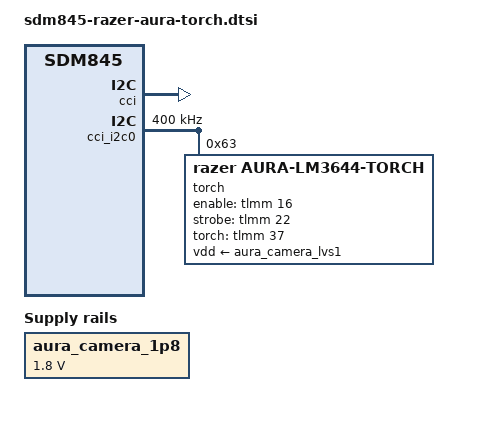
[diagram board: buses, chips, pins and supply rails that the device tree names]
// SPDX-License-Identifier: GPL-2.0-only
/* Stock RC2 camera CCI0, 0x63, HWEN16 / STROBE22 / TORCH37, LVS1 1.8 V. */
/ {
	aura_camera_1p8: regulator-camera-1p8 {
		compatible = "regulator-fixed";
		regulator-name = "aura-camera-1p8";
		regulator-min-microvolt = <1800000>;
		regulator-max-microvolt = <1800000>;
	};
};
&apps_rsc {
	regulators-0 {
		vin-lvs-1-2-supply = <&aura_camera_1p8>;
		aura_camera_lvs1: lvs1 {
			regulator-min-microvolt = <1800000>;
			regulator-max-microvolt = <1800000>;
		};
	};
};
&tlmm {
	aura_torch_pins: torch-pins-state {
		pins = "gpio16", "gpio22", "gpio37";
		function = "gpio";
		drive-strength = <2>;
		bias-pull-down;
	};
};
&cci {
	status = "okay";
	/* Only the first camera control bus is needed for torch bring-up. */
	pinctrl-0 = <&cci0_default>;
	pinctrl-1 = <&cci0_sleep>;
};
&cci_i2c0 {
	clock-frequency = <400000>;
	torch@63 {
		compatible = "razer,aura-lm3644-torch";
		reg = <0x63>;
		vdd-supply = <&aura_camera_lvs1>;
		pinctrl-names = "default";
		pinctrl-0 = <&aura_torch_pins>;
		enable-gpios = <&tlmm 16 GPIO_ACTIVE_HIGH>;
		strobe-gpios = <&tlmm 22 GPIO_ACTIVE_HIGH>;
		torch-gpios = <&tlmm 37 GPIO_ACTIVE_HIGH>;
	};
};
&cci_i2c1 { status = "disabled"; };
